# TREMO register map
File version: 1.6.2
CPU: CM4 r0p1, little endian, MPU, FPU, 3 interrupt priority bits
Registers are 32-bit, read-write, reset 0x0 unless marked. A register's access mark holds for its fields unless they carry their own. Offsets are from the block's base; [hi:lo] are bit positions.

## UART0 — UART
Base 0x40003000
Same registers: UART1 0x40004000, UART2 0x40010000, UART3 0x40011000
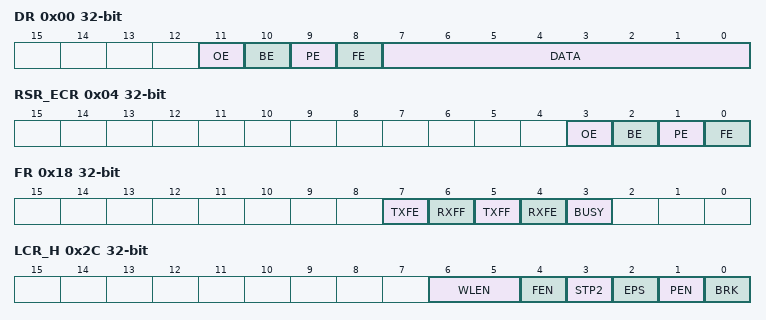
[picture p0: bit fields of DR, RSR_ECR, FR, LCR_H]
0x00 DR (reset mask 0xFF) — data register
  [11] OE ro — Overrun error flag
  [10] BE ro — Break error flag
  [9] PE ro — Parity error flag
  [8] FE ro — Framing error flag
  [7:0] DATA — Transmit data character/Receive data character
0x04 RSR_ECR — receive status register/error clear register
  [3] OE — Overrun error flag
  [2] BE — Break error flag
  [1] PE — Parity error flag
  [0] FE — Framing error flag
0x18 FR ro — flag register
  [7] TXFE — Transmit FIFO empty
  [6] RXFF — Receive FIFO full
  [5] TXFF — Transmit FIFO full
  [4] RXFE — Receive FIFO empty
  [3] BUSY — UART busy
0x20 ILPR — IRDA low power counter register
  [7:0] ILPDVSR — low-power divisor value
0x24 IBRD — integer baudrate register
  [15:0] BAUD_DIVINT — The integer baud rate divisor
0x28 FBRD — fractional baudrate register
  [5:0] BAUD_DIVFRAC — The fractional baud rate divisor
0x2C LCR_H — line control register
  [6:5] WLEN — Word length
  [4] FEN — FIFO enable
  [3] STP2 — Stop bits selection
  [2] EPS — Even parity selection
  [1] PEN — Parity enable
  [0] BRK — Send break
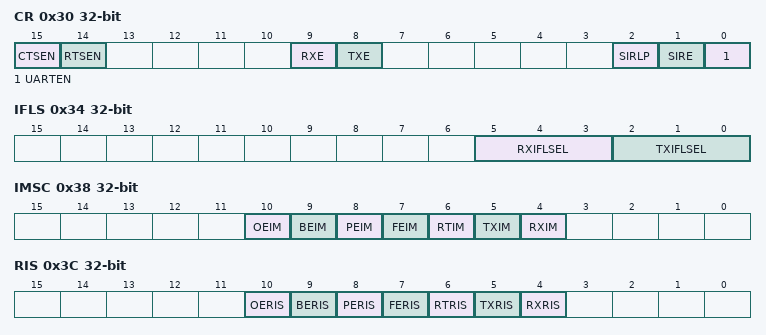
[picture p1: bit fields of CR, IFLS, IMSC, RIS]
0x30 CR — control register
  [15] CTSEN — CTS hardware flow control enable
  [14] RTSEN — RTS hardware flow control enable
  [9] RXE — Receive enable
  [8] TXE — Transmit enable
  [2] SIRLP — Low-power IrDA SIR encoding mode selection
  [1] SIRE — IrDA SIR enable
  [0] UARTEN — UART enable
0x34 IFLS — interrupt fifo level select register
  [5:3] RXIFLSEL — Receive interrupt FIFO level selection
  [2:0] TXIFLSEL — Transmit interrupt FIFO level selection
0x38 IMSC — interrupt mask set/clear register
  [10] OEIM — Overrun error interrupt mask bit
  [9] BEIM — Break error interrupt mask bit
  [8] PEIM — Parity error interrupt mask bit
  [7] FEIM — Framing error interrupt mask bit
  [6] RTIM — Receive timeout interrupt mask bit
  [5] TXIM — Transmission completion interrupt mask bit
  [4] RXIM — Reception completion interrupt mask bit
0x3C RIS ro — raw interrupt status register
  [10] OERIS — Overrun error raw interrupt status
  [9] BERIS — Break error raw interrupt status
  [8] PERIS — Parity error raw interrupt status
  [7] FERIS — Framing error raw interrupt status
  [6] RTRIS — Receive timeout raw interrupt status
  [5] TXRIS — Transmission completion raw interrupt status
  [4] RXRIS — Reception completion raw interrupt status
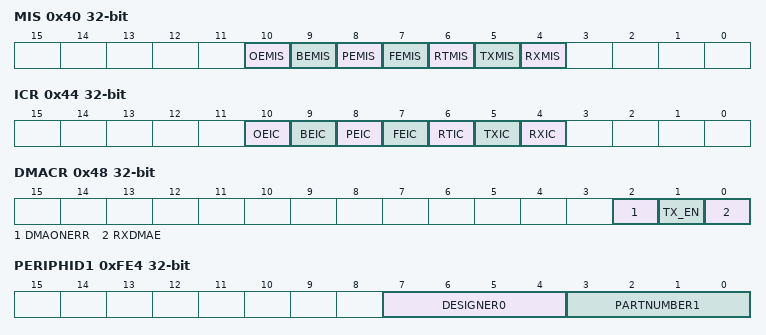
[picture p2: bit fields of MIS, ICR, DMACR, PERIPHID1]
0x40 MIS ro — masked interrupt status register
  [10] OEMIS — Overrun error masked interrupt status
  [9] BEMIS — Break error masked interrupt status
  [8] PEMIS — Parity error masked interrupt status
  [7] FEMIS — Framing error masked interrupt status
  [6] RTMIS — Receive timeout masked interrupt status
  [5] TXMIS — Transmission completion masked interrupt status
  [4] RXMIS — Reception completion masked interrupt status
0x44 ICR wo — interrupt clear register
  [10] OEIC — Overrun error interrupt clear
  [9] BEIC — Break error interrupt clear
  [8] PEIC — Parity error interrupt clear
  [7] FEIC — Framing error interrupt clear
  [6] RTIC — Receive timeout interrupt clear
  [5] TXIC — Transmission completion interrupt clear
  [4] RXIC — Reception completion interrupt clear
0x48 DMACR — DMA control register
  [2] DMAONERR
  [1] TX_EN — Transmit DMA enable
  [0] RXDMAE — Receive DMA enable
0xFD0 PCELLID0 ro — ID register
  [7:0] CELLID0
0xFD4 PCELLID1 ro (reset mask 0xFF) — ID register
  [31:0] CELLID1
0xFD8 PCELLID2 8-bit ro — ID register
  [7:0] CELLID2
0xFDC PCELLID3 8-bit ro — ID register
  [7:0] CELLID3
0xFE0 PERIPHID0 ro — ID register
  [7:0] PARTNUMBER0
0xFE4 PERIPHID1 ro — ID register
  [7:4] DESIGNER0, [3:0] PARTNUMBER1
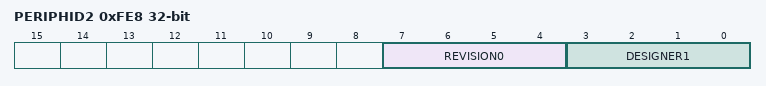
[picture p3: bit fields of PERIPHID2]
0xFE8 PERIPHID2 ro — ID register
  [7:4] REVISION0, [3:0] DESIGNER1
0xFEC PERIPHID3 ro — ID register
  [7:0] CONFIGURATION
